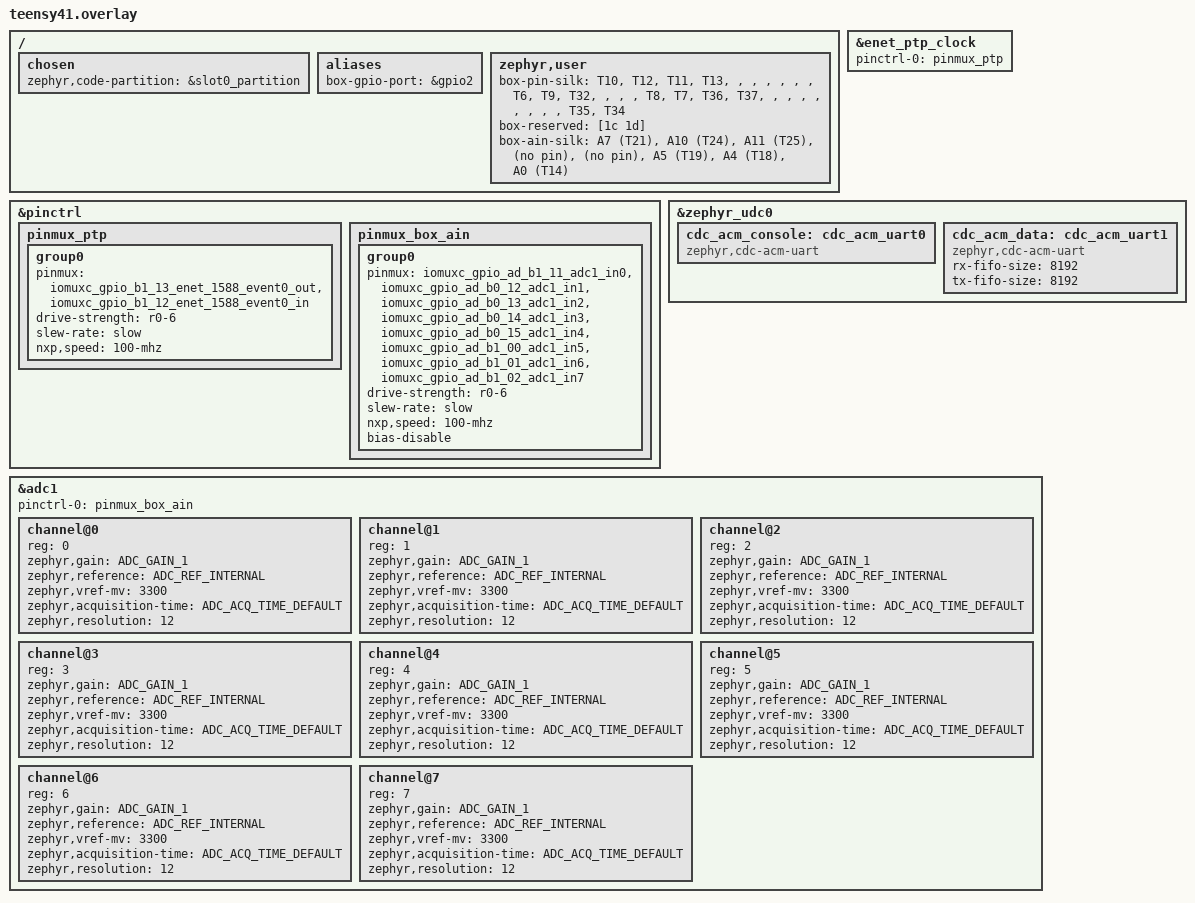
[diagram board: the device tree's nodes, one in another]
/*
 * extio-zephyr on a PJRC Teensy 4.1 (i.MX RT1062) -- the wired test system.
 *
 * The RT1062 drives the same NXP peripherals through the same Zephyr drivers as
 * the RW612: `nxp,enet` + `nxp,enet-ptp-clock` for Ethernet/1588, and a USB-HS
 * device controller. Teensy 4.1's board DTS already enables ENET with a
 * ti,dp83825 PHY (RMII) -- add a magjack and it's a wired extio box.
 *
 * NOTE: no radio on Teensy, so block #6's BLE ingress is excluded (see
 * boards/teensy41.conf -- no CONFIG_BT). Everything else builds.
 */

#include <zephyr/dt-bindings/adc/adc.h>   /* ADC_ACQ_TIME_DEFAULT */
/ {
	/* Where the APP links when there is a bootloader in front of it. Read ONLY
	 * when CONFIG_BOOTLOADER_MCUBOOT selects USE_DT_CODE_PARTITION, i.e. under
	 * --sysbuild; the plain `west build -b teensy41 .` ignores it and keeps
	 * CONFIG_FLASH_LOAD_OFFSET=0. The PJRC board DTS sets no zephyr,code-partition
	 * of its own, which is why this has to be here at all. */
	chosen {
		zephyr,code-partition = &slot0_partition;
	};

	aliases {
		box-gpio-port     = &gpio2;   /* box pin n -> gpio2.n (3 = board LED) */
	};

	zephyr,user {
		/* ---- SILK: what is PRINTED on the board, per box pin ----
		 * Same scheme as teensy40.overlay (which see): positional, index =
		 * box pin = gpio2 bit, "" where the pad is not bonded out. The 4.1
		 * brings four MORE gpio2 pads to the header than the 4.0: B1_02/03
		 * (pins 36/37) and B1_12/13 (pins 35/34) -- the latter pair is
		 * claimed by the 1588 EVENT pinmux below, hence `box-reserved`.
		 * Values from Zephyr's board doc pin->pad table crossed with the
		 * GPIO2 bank, not from the silkscreen. */
		box-pin-silk = "T10","T12","T11","T13","","","","","","",
			       "T6","T9","T32","","","","T8","T7","T36","T37",
			       "","","","","","","","","T35","T34";

		/* B1_12/13 (box pins 28/29 = silk 35/34) belong to the ENET 1588
		 * EVENT pinmux -- see &pinctrl below. Reserved so `pin 28 mode out`
		 * cannot re-mux a pad the PTP block is holding. */
		box-reserved = [1c 1d];

		/* ain channel -> what is printed. Identical to the teensy40: the
		 * same eight adc1 inputs land on the same silk names on both
		 * boards (on the 4.1, A10/A11 are header pins 24/25 rather than
		 * bottom pads). reg IS the hardware ADC input, so silkscreen A0
		 * is channel 7 -- the teensy40.overlay note has the whole map. */
		box-ain-silk = "A7 (T21)","A10 (T24)","A11 (T25)","(no pin)","(no pin)",
			       "A5 (T19)","A4 (T18)","A0 (T14)";
	};

	/* zephyr,console stays on lpuart6 (Teensy pins 0/1) for Zephyr's own printk
	 * and driver LOG (dev serial adapter); the box CLI shell owns the USB
	 * console CDC -- separate devices, no conflict. */
};

/* Settings storage + the MCUboot A/B layout: boards/teensy41_partitions.dtsi,
 * because MCUboot needs the IDENTICAL table and cannot see this file. The whole
 * layout -- including why storage shrank to 32 KB without moving, and why
 * nothing reaches the part's final sector -- is documented there.
 *
 * Present unconditionally and inert without --sysbuild: CONFIG_BOOTLOADER_MCUBOOT
 * is what selects USE_DT_CODE_PARTITION, so the plain build ignores the chosen
 * node above and still links at flash base.
 *
 * Writing the flash the chip XIP-executes from IS the hazard that made this look
 * unworkable for a while -- but CONFIG_FLASH_MCUX_FLEXSPI_XIP=y (enabled
 * automatically by the RT10xx SoC defconfig) relocates the erase/write path to
 * ITCM, and it is validated on hardware, now including a full MCUboot swap on
 * the teensy40. The old "hard-faults at boot" verdict was actually a main-thread
 * stack overflow; see PORTING.md.
 *
 * HalfKay does NOT full-chip-erase on reflash -- saved settings survive a
 * reflash, verified 2026-07-23. */
#include "teensy41_partitions.dtsi"

/* The ENET IEEE-1588 clock is `disabled` in the RT1060 SoC dtsi exactly as it is
 * on the RW612 -- enable it so PTP_CLOCK_NXP_ENET instantiates the clock.
 *
 * pinctrl is REQUIRED, not optional: ptp_clock_nxp_enet_init()'s only failure
 * path is pinctrl_apply_state(PINCTRL_STATE_DEFAULT), so a bare status="okay"
 * (no default state) fails init and device_is_ready() reports false -- which is
 * what `ptp_ready=0` was. Mirrors the RT1060 EVK, same SoC family.
 *
 * The 1588 EVENT pads are for external timestamp capture/trigger, which we do
 * not use -- they are here to give the driver a valid state to apply. They
 * lived on AD_B1_02/03 (pins 14/15, "otherwise LPUART2") until the ADC arrived:
 * AD_B1_02 is adc1_in7, i.e. silkscreen A0, and two pinctrl states claiming one
 * pad means whichever device initialises LAST owns the mux -- an A0 that reads
 * the 1588 event line by coupling would be exactly the plausible-wrong-pad
 * failure the channel map exists to prevent. EVENT0 has alternates on B1_12/13
 * (pins 35/34, otherwise UART5, which this box does not use), so the claim
 * moves there: analog stays identical to the teensy40, and those two pads stop
 * being box pins (28/29 -- reserved in zephyr,user above).
 */
&pinctrl {
	pinmux_ptp: pinmux_ptp {
		group0 {
			pinmux = <&iomuxc_gpio_b1_13_enet_1588_event0_out>,
				 <&iomuxc_gpio_b1_12_enet_1588_event0_in>;
			drive-strength = "r0-6";
			slew-rate = "slow";
			nxp,speed = "100-mhz";
		};
	};
};

&enet_ptp_clock {
	status = "okay";
	pinctrl-0 = <&pinmux_ptp>;
	pinctrl-names = "default";
};

/* Same two CDC-ACM instances as the RW612 build: the human text console and the
 * binary frame pipe (data + config).
 *
 * ORDER IS PART OF THE CONTRACT -- console FIRST, data SECOND. Instance order
 * sets USB interface numbering, and the dserv host module looks for the data
 * pipe at if02 on Linux (`*extio*if02*`) and the *3 tty on macOS. Declare data
 * first and dserv opens the CONSOLE instead, steals its bytes, and reopens it
 * every 2 s -- see README "Console status". */
&zephyr_udc0 {
	cdc_acm_console: cdc_acm_uart0 {
		compatible = "zephyr,cdc-acm-uart";
	};
	cdc_acm_data: cdc_acm_uart1 {
		compatible = "zephyr,cdc-acm-uart";
		/* the frame pipe's class-level fifos, widened to match the app
		 * rings in box_net_usb.c (8 KB): the 1024 B defaults were one
		 * of the two stages behind the ~8-frame burst cliff */
		rx-fifo-size = <8192>;
		tx-fifo-size = <8192>;
	};
};

/*
 * ---- ANALOG: the RT1062's on-chip 12-bit SAR (adc1) ----
 *
 * BYTE-FOR-BYTE the teensy40's analog front end -- same silicon, same eight
 * inputs, same silk names -- so a group config moves between the two boards
 * unchanged. boards/teensy40.overlay carries the canonical note: reg IS the
 * hardware input on this converter (channel_id goes straight into
 * ADC_HC[ADCH]), the pad map, and why all eight channels are declared.
 *
 * The one 4.1-specific consequence is above: AD_B1_02 (in7 = A0) was the 1588
 * EVENT pad, so pinmux_ptp moved to B1_12/13.
 */
&pinctrl {
	pinmux_box_ain: pinmux_box_ain {
		group0 {
			pinmux = <&iomuxc_gpio_ad_b1_11_adc1_in0>,
				 <&iomuxc_gpio_ad_b0_12_adc1_in1>,
				 <&iomuxc_gpio_ad_b0_13_adc1_in2>,
				 <&iomuxc_gpio_ad_b0_14_adc1_in3>,
				 <&iomuxc_gpio_ad_b0_15_adc1_in4>,
				 <&iomuxc_gpio_ad_b1_00_adc1_in5>,
				 <&iomuxc_gpio_ad_b1_01_adc1_in6>,
				 <&iomuxc_gpio_ad_b1_02_adc1_in7>;
			drive-strength = "r0-6";
			slew-rate = "slow";
			nxp,speed = "100-mhz";
			/* NOT OPTIONAL for analog: Zephyr encodes PKE as
			 * !bias-disable (soc/nxp/imxrt/imxrt10xx/pinctrl_soc.h),
			 * so omitting this leaves the pad KEEPER on -- a weak
			 * digital latch that fights the source and compresses a
			 * pot's apparent range (the classic RT10xx analog trap;
			 * PJRC's core clears PKE for analog pins for the same
			 * reason). Found 2026-08-20 as a joystick that could not
			 * reach the rails. */
			bias-disable;
		};
	};
};

box_adc: &adc1 {
	status = "okay";
	pinctrl-0 = <&pinmux_box_ain>;
	pinctrl-names = "default";
	#address-cells = <1>;
	#size-cells = <0>;

	channel@0 { reg = <0>; zephyr,gain = "ADC_GAIN_1";
		zephyr,reference = "ADC_REF_INTERNAL"; zephyr,vref-mv = <3300>;
		zephyr,acquisition-time = <ADC_ACQ_TIME_DEFAULT>; zephyr,resolution = <12>; };
	channel@1 { reg = <1>; zephyr,gain = "ADC_GAIN_1";
		zephyr,reference = "ADC_REF_INTERNAL"; zephyr,vref-mv = <3300>;
		zephyr,acquisition-time = <ADC_ACQ_TIME_DEFAULT>; zephyr,resolution = <12>; };
	channel@2 { reg = <2>; zephyr,gain = "ADC_GAIN_1";
		zephyr,reference = "ADC_REF_INTERNAL"; zephyr,vref-mv = <3300>;
		zephyr,acquisition-time = <ADC_ACQ_TIME_DEFAULT>; zephyr,resolution = <12>; };
	channel@3 { reg = <3>; zephyr,gain = "ADC_GAIN_1";
		zephyr,reference = "ADC_REF_INTERNAL"; zephyr,vref-mv = <3300>;
		zephyr,acquisition-time = <ADC_ACQ_TIME_DEFAULT>; zephyr,resolution = <12>; };
	channel@4 { reg = <4>; zephyr,gain = "ADC_GAIN_1";
		zephyr,reference = "ADC_REF_INTERNAL"; zephyr,vref-mv = <3300>;
		zephyr,acquisition-time = <ADC_ACQ_TIME_DEFAULT>; zephyr,resolution = <12>; };
	channel@5 { reg = <5>; zephyr,gain = "ADC_GAIN_1";
		zephyr,reference = "ADC_REF_INTERNAL"; zephyr,vref-mv = <3300>;
		zephyr,acquisition-time = <ADC_ACQ_TIME_DEFAULT>; zephyr,resolution = <12>; };
	channel@6 { reg = <6>; zephyr,gain = "ADC_GAIN_1";
		zephyr,reference = "ADC_REF_INTERNAL"; zephyr,vref-mv = <3300>;
		zephyr,acquisition-time = <ADC_ACQ_TIME_DEFAULT>; zephyr,resolution = <12>; };
	channel@7 { reg = <7>; zephyr,gain = "ADC_GAIN_1";
		zephyr,reference = "ADC_REF_INTERNAL"; zephyr,vref-mv = <3300>;
		zephyr,acquisition-time = <ADC_ACQ_TIME_DEFAULT>; zephyr,resolution = <12>; };
};
